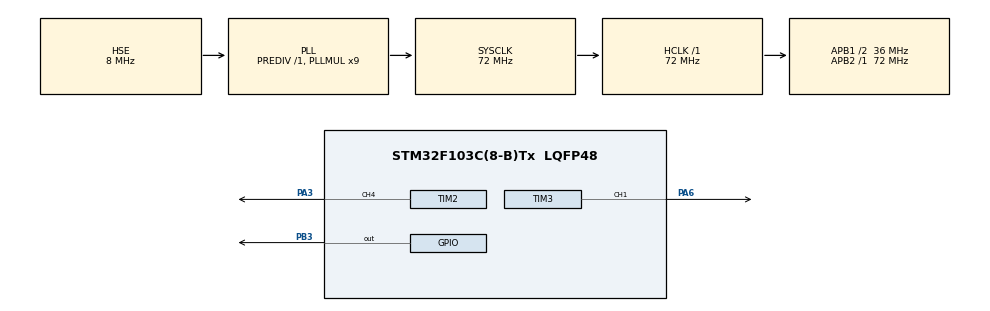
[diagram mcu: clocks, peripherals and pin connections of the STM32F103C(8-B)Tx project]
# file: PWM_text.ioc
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FREERTOS.Tasks01=defaultTask,0,128,StartDefaultTask,Default,NULL,Dynamic,NULL,NULL
Mcu.Family=STM32F1
Mcu.Name=STM32F103C(8-B)Tx
Mcu.Package=LQFP48
NVIC.PriorityGroup=NVIC_PRIORITYGROUP_4
NVIC.TIM1_UP_IRQn=true\:15\:0\:false\:false\:true\:false\:false\:true
NVIC.TimeBase=TIM1_UP_IRQn
NVIC.TimeBaseIP=TIM1
PA13.Mode=Serial_Wire
PA13.Signal=SYS_JTMS-SWDIO
PA14.Mode=Serial_Wire
PA14.Signal=SYS_JTCK-SWCLK
PA3.Signal=S_TIM2_CH4
PA6.Signal=S_TIM3_CH1
PB3.Signal=GPIO_Output
PD0-OSC_IN.Mode=HSE-External-Oscillator
PD0-OSC_IN.Signal=RCC_OSC_IN
PD1-OSC_OUT.Mode=HSE-External-Oscillator
PD1-OSC_OUT.Signal=RCC_OSC_OUT
ProjectManager.HeapSize=0x200
ProjectManager.StackSize=0x400
ProjectManager.TargetToolchain=MDK-ARM V5
RCC.AHBFreq_Value=72000000
RCC.APB1CLKDivider=RCC_HCLK_DIV2
RCC.APB1Freq_Value=36000000
RCC.APB1TimFreq_Value=72000000
RCC.APB2Freq_Value=72000000
RCC.APB2TimFreq_Value=72000000
RCC.HCLKFreq_Value=72000000
RCC.PLLMUL=RCC_PLL_MUL9
RCC.PLLSourceVirtual=RCC_PLLSOURCE_HSE
RCC.SYSCLKFreq_VALUE=72000000
RCC.SYSCLKSource=RCC_SYSCLKSOURCE_PLLCLK
RCC.USBFreq_Value=72000000
SH.S_TIM2_CH4.0=TIM2_CH4,PWM Generation4 CH4
SH.S_TIM3_CH1.0=TIM3_CH1,PWM Generation1 CH1
TIM2.AutoReloadPreload=TIM_AUTORELOAD_PRELOAD_ENABLE
TIM2.Channel-PWM\ Generation4\ CH4=TIM_CHANNEL_4
TIM2.OCPolarity_4=TIM_OCPOLARITY_HIGH
TIM2.Period=1000
TIM2.Prescaler=360-1
TIM3.AutoReloadPreload=TIM_AUTORELOAD_PRELOAD_ENABLE
TIM3.Channel-PWM\ Generation1\ CH1=TIM_CHANNEL_1
TIM3.ClockDivision=TIM_CLOCKDIVISION_DIV1
TIM3.OCFastMode_PWM-PWM\ Generation1\ CH1=TIM_OCFAST_DISABLE
TIM3.OCPolarity_1=TIM_OCPOLARITY_HIGH
TIM3.Period=1000
TIM3.Prescaler=360-1
VP_FREERTOS_VS_CMSIS_V1.Mode=CMSIS_V1
VP_SYS_VS_tim1.Mode=TIM1
VP_TIM2_VS_ClockSourceINT.Mode=Internal
VP_TIM3_VS_ClockSourceINT.Mode=Internal
board=custom

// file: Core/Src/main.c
/* USER CODE BEGIN Header */
/**
  ******************************************************************************
  * @file           : main.c
  * @brief          : Main program body
  ******************************************************************************
  * @attention
  *
  * Copyright (c) 2022 STMicroelectronics.
  * All rights reserved.
  *
  * This software is licensed under terms that can be found in the LICENSE file
  * in the root directory of this software component.
  * If no LICENSE file comes with this software, it is provided AS-IS.
  *
  ******************************************************************************
  */
/* USER CODE END Header */
#include "main.h"
#include "cmsis_os.h"
#include "tim.h"
#include "gpio.h"

void SystemClock_Config(void);
void MX_FREERTOS_Init(void);

int main(void)
{

  /* MCU Configuration--------------------------------------------------------*/

  /* Reset of all peripherals, Initializes the Flash interface and the Systick. */
  HAL_Init();

  /* Configure the system clock */
  SystemClock_Config();

  /* Initialize all configured peripherals */
  MX_GPIO_Init();
  MX_TIM2_Init();
  MX_TIM3_Init();
  /* USER CODE BEGIN 2 */

	HAL_TIM_PWM_Start(&htim2,TIM_CHANNEL_4);
	HAL_TIM_PWM_Start(&htim3,TIM_CHANNEL_1);
__HAL_TIM_SetCompare(&htim2,TIM_CHANNEL_4,1000);
//	__HAL_TIM_SetCompare(&htim3,TIM_CHANNEL_1,500);

//	__HAL_TIM_SetCompare(&htim2,TIM_CHANNEL_4,200);
//	__HAL_TIM_SetCompare(&htim3,TIM_CHANNEL_1,200);
  /* USER CODE END 2 */

  /* Call init function for freertos objects (in freertos.c) */
  MX_FREERTOS_Init();
  /* Start scheduler */
  osKernelStart();

  /* We should never get here as control is now taken by the scheduler */
  /* Infinite loop */
  while (1)
  {

  }
}

void SystemClock_Config(void)
{
  RCC_OscInitTypeDef RCC_OscInitStruct = {0};
  RCC_ClkInitTypeDef RCC_ClkInitStruct = {0};

  /** Initializes the RCC Oscillators according to the specified parameters
  * in the RCC_OscInitTypeDef structure.
  */
  RCC_OscInitStruct.OscillatorType = RCC_OSCILLATORTYPE_HSE;
  RCC_OscInitStruct.HSEState = RCC_HSE_ON;
  RCC_OscInitStruct.HSEPredivValue = RCC_HSE_PREDIV_DIV1;
  RCC_OscInitStruct.HSIState = RCC_HSI_ON;
  RCC_OscInitStruct.PLL.PLLState = RCC_PLL_ON;
  RCC_OscInitStruct.PLL.PLLSource = RCC_PLLSOURCE_HSE;
  RCC_OscInitStruct.PLL.PLLMUL = RCC_PLL_MUL9;
  if (HAL_RCC_OscConfig(&RCC_OscInitStruct) != HAL_OK)
  {
    Error_Handler();
  }
  /** Initializes the CPU, AHB and APB buses clocks
  */
  RCC_ClkInitStruct.ClockType = RCC_CLOCKTYPE_HCLK|RCC_CLOCKTYPE_SYSCLK
                              |RCC_CLOCKTYPE_PCLK1|RCC_CLOCKTYPE_PCLK2;
  RCC_ClkInitStruct.SYSCLKSource = RCC_SYSCLKSOURCE_PLLCLK;
  RCC_ClkInitStruct.AHBCLKDivider = RCC_SYSCLK_DIV1;
  RCC_ClkInitStruct.APB1CLKDivider = RCC_HCLK_DIV2;
  RCC_ClkInitStruct.APB2CLKDivider = RCC_HCLK_DIV1;

  if (HAL_RCC_ClockConfig(&RCC_ClkInitStruct, FLASH_LATENCY_2) != HAL_OK)
  {
    Error_Handler();
  }
}

void HAL_TIM_PeriodElapsedCallback(TIM_HandleTypeDef *htim)
{
  if (htim->Instance == TIM1) {
    HAL_IncTick();
  }
}

void Error_Handler(void)
{
  __disable_irq();
  while (1)
  {
  }
}

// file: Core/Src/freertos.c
/* USER CODE BEGIN Header */
/**
  ******************************************************************************
  * File Name          : freertos.c
  * Description        : Code for freertos applications
  ******************************************************************************
  * @attention
  *
  * Copyright (c) 2022 STMicroelectronics.
  * All rights reserved.
  *
  * This software is licensed under terms that can be found in the LICENSE file
  * in the root directory of this software component.
  * If no LICENSE file comes with this software, it is provided AS-IS.
  *
  ******************************************************************************
  */
/* USER CODE END Header */

#include "FreeRTOS.h"
#include "task.h"
#include "main.h"
#include "cmsis_os.h"

/* USER CODE BEGIN Includes */
#include "tim.h"
/* USER CODE END Includes */

osThreadId defaultTaskHandle;

void StartDefaultTask(void const * argument);

void MX_FREERTOS_Init(void); /* (MISRA C 2004 rule 8.1) */

/* GetIdleTaskMemory prototype (linked to static allocation support) */
void vApplicationGetIdleTaskMemory( StaticTask_t **ppxIdleTaskTCBBuffer, StackType_t **ppxIdleTaskStackBuffer, uint32_t *pulIdleTaskStackSize );

/* USER CODE BEGIN GET_IDLE_TASK_MEMORY */
static StaticTask_t xIdleTaskTCBBuffer;
static StackType_t xIdleStack[configMINIMAL_STACK_SIZE];

void vApplicationGetIdleTaskMemory( StaticTask_t **ppxIdleTaskTCBBuffer, StackType_t **ppxIdleTaskStackBuffer, uint32_t *pulIdleTaskStackSize )
{
  *ppxIdleTaskTCBBuffer = &xIdleTaskTCBBuffer;
  *ppxIdleTaskStackBuffer = &xIdleStack[0];
  *pulIdleTaskStackSize = configMINIMAL_STACK_SIZE;
  /* place for user code */
}
/* USER CODE END GET_IDLE_TASK_MEMORY */

void MX_FREERTOS_Init(void) {

  /* Create the thread(s) */
  /* definition and creation of defaultTask */
  osThreadDef(defaultTask, StartDefaultTask, osPriorityNormal, 0, 128);
  defaultTaskHandle = osThreadCreate(osThread(defaultTask), NULL);

}

void StartDefaultTask(void const * argument)
{
  /* USER CODE BEGIN StartDefaultTask */
	int  t =0;
  /* Infinite loop */
  for(;;)
  {
		if(t > 1000)
		{
			t = 0;
			__HAL_TIM_SetCompare(&htim2,TIM_CHANNEL_4,t);
			osDelay(3000);
		}
		t+=100;
__HAL_TIM_SetCompare(&htim2,TIM_CHANNEL_4,t);
	HAL_GPIO_TogglePin(GPIOB,GPIO_PIN_3);
    osDelay(500);
  }
  /* USER CODE END StartDefaultTask */
}
